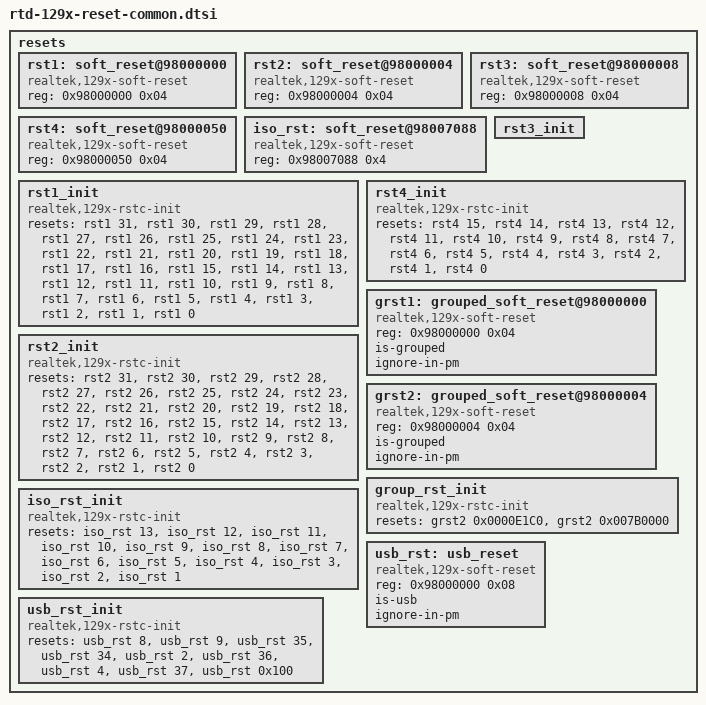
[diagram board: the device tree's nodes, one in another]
/* PLEASE include this file inside a node */
resets {
    #address-cells = <1>;
    #size-cells = <1>;
    ranges;

    /* reset_controller */
    rst1: soft_reset@98000000 {
        reg = <0x98000000 0x04>;
        compatible = "realtek,129x-soft-reset";
        #reset-cells = <1>;
    };

    rst2: soft_reset@98000004 {
        reg = <0x98000004 0x04>;
        compatible = "realtek,129x-soft-reset";
        #reset-cells = <1>;
    };

    rst3: soft_reset@98000008 {
        reg = <0x98000008 0x04>;
        compatible = "realtek,129x-soft-reset";
        #reset-cells = <1>;
    };

    rst4: soft_reset@98000050 {
        reg = <0x98000050 0x04>;
        compatible = "realtek,129x-soft-reset";
        #reset-cells = <1>;
    };

    iso_rst: soft_reset@98007088 {
        reg = <0x98007088 0x4>;
        compatible = "realtek,129x-soft-reset";
        #reset-cells = <1>;
    };

    /* reset_control */
    rst1_init {
        compatible = "realtek,129x-rstc-init";
        resets =
            <&rst1 31>, <&rst1 30>, <&rst1 29>, <&rst1 28>,
            <&rst1 27>, <&rst1 26>, <&rst1 25>, <&rst1 24>,
            <&rst1 23>, <&rst1 22>, <&rst1 21>, <&rst1 20>,
            <&rst1 19>, <&rst1 18>, <&rst1 17>, <&rst1 16>,
            <&rst1 15>, <&rst1 14>, <&rst1 13>, <&rst1 12>,
            <&rst1 11>, <&rst1 10>, <&rst1  9>, <&rst1  8>,
            <&rst1  7>, <&rst1  6>, <&rst1  5>, <&rst1  4>,
            <&rst1  3>, <&rst1  2>, <&rst1  1>, <&rst1  0>;
        reset-names =
            "rstn_rsa",          "rstn_mipi",           "rstn_nf",        "rstn_ae",
            "rstn_tp",           "rstn_md",             "rstn_cp",        "rstn_dc_phy",
            "rstn_dcu",          "rstn_se",             "rstn_lvds",      "rstn_vo",
            "rstn_tve",          "rstn_gpu",            "rstn_aio",       "rstn_etn",
            "rstn_ve3",          "rstn_ve2",            "rstn_ve1",       "rstn_hdmi",
            "sata_func_exist_0", "rstn_sata_phy_pow_0", "*rstn_usb_phy1", "*rstn_usb_phy0",
            "rstn_sata_phy_0",   "rstn_usb",            "rstn_sata_0",    "rstn_usb3_p0_mdio",
            "rstn_gspi",         "*rstn_usb3_phy0_pow", "rstn_nat",       "rstn_misc";
    };

    rst2_init {
        compatible = "realtek,129x-rstc-init";
        resets =
            <&rst2 31>, <&rst2 30>, <&rst2 29>, <&rst2 28>,
            <&rst2 27>, <&rst2 26>, <&rst2 25>, <&rst2 24>,
            <&rst2 23>, <&rst2 22>, <&rst2 21>, <&rst2 20>,
            <&rst2 19>, <&rst2 18>, <&rst2 17>, <&rst2 16>,
            <&rst2 15>, <&rst2 14>, <&rst2 13>, <&rst2 12>,
            <&rst2 11>, <&rst2 10>, <&rst2  9>, <&rst2  8>,
            <&rst2  7>, <&rst2  6>, <&rst2  5>, <&rst2  4>,
            <&rst2  3>, <&rst2  2>, <&rst2  1>, <&rst2  0>;
        reset-names =
            "rstn_sds_phy",        "rstn_cbus_tx",        "rstn_misc_sc",      "rstn_ur1",
            "rstn_ur2",            "rstn_i2c_1",          "rstn_i2c_2",        "rstn_i2c_3",
            "rstn_i2c_4",          "rstn_pcie1_nonstich", "rstn_pcie1_power",  "rstn_pcie1_core",
            "rstn_pcie1_stitch",   "rstn_i2c_5",          "rstn_pcie1",        "rstn_pcie1_phy",
            "rstn_pcie0_nonstich", "rstn_pcie0_power",    "rstn_pcie0_core",   "rstn_sdio",
            "rstn_emmc",           "rstn_cr",             "rstn_pcr_cnt",      "rstn_pcie0",
            "rstn_pcie0_phy",      "rstn_pcie0_stitch",   "rstn_usb3_p1_mdio", "*rstn_usb3_phy1_pow",
            "*rstn_usb_phy2",      "*rstn_usb_phy3",      "rstn_jpeg",         "rstn_acpu";
    };

    rst3_init {
    };

    rst4_init {
        compatible = "realtek,129x-rstc-init";
        resets =
            <&rst4 15>, <&rst4 14>, <&rst4 13>, <&rst4 12>,
            <&rst4 11>, <&rst4 10>, <&rst4  9>, <&rst4  8>,
            <&rst4  7>, <&rst4  6>, <&rst4  5>, <&rst4  4>,
            <&rst4  3>, <&rst4  2>, <&rst4  1>, <&rst4  0>;
        reset-names =
            "rstn_disp",           "rstn_pcie1_phy_mdio", "rstn_pcie0_phy_mdio", "rstn_hdmirx_wrap",
            "rstn_fan",            "rstn_sata_1",         "rstn_sata_phy_1",     "sata_func_exist_1",
            "rstn_sata_phy_pow_1", "rstn_cbusrx",         "rstn_hdmirx",         "rstn_dcphy_ssc_dig",
            "rstn_dcphy_ldo",      "rstn_dcphy_ptr",      "rstn_dcphy_alert_rx", "rstn_dcphy_crt";
    };

    iso_rst_init {
        compatible = "realtek,129x-rstc-init";
        resets =
            <&iso_rst 13>, <&iso_rst 12>, <&iso_rst 11>, <&iso_rst 10>,
            <&iso_rst  9>, <&iso_rst  8>, <&iso_rst  7>, <&iso_rst  6>,
            <&iso_rst  5>, <&iso_rst  4>, <&iso_rst  3>, <&iso_rst  2>,
            <&iso_rst  1>;
        reset-names =
            "iso_rstn_cbus",   "iso_rstn_i2c_1", "iso_rstn_i2c_0", "iso_rstn_gphy",
            "iso_rstn_gmac",   "iso_rstn_ur0",   "iso_rstn_efuse", "iso_rstn_cbusrx",
            "iso_rstn_cbustx", "iso_rstn_dp",    "iso_rstn_cec1",  "iso_rstn_cec0",
            "iso_rstn_ir";
    };

    grst1: grouped_soft_reset@98000000 {
        reg = <0x98000000 0x04>;
        compatible = "realtek,129x-soft-reset";
        #reset-cells = <1>;
        is-grouped;
        ignore-in-pm;
    };

    grst2: grouped_soft_reset@98000004 {
        reg = <0x98000004 0x04>;
        compatible = "realtek,129x-soft-reset";
        #reset-cells = <1>;
        is-grouped;
        ignore-in-pm;
    };

    group_rst_init {
        compatible = "realtek,129x-rstc-init";
        reset-names =
            "rstn_pcie0_all",
            "rstn_pcie1_all";
        resets =
            <&grst2 0x0000E1C0>,
            <&grst2 0x007B0000>;
    };

    usb_rst: usb_reset {
        reg = <0x98000000 0x08>;
        #reset-cells = <1>;
        compatible = "realtek,129x-soft-reset";
        is-usb;
        ignore-in-pm;
    };

    usb_rst_init {
       compatible = "realtek,129x-rstc-init";
       resets =
            <&usb_rst  8>,
            <&usb_rst  9>,
            <&usb_rst 35>,
            <&usb_rst 34>,
            <&usb_rst  2>,
            <&usb_rst 36>,
            <&usb_rst  4>,
            <&usb_rst 37>,
            <&usb_rst 0x100>; /* special case */
       reset-names =
            "rstn_usb_phy0",
            "rstn_usb_phy1",
            "rstn_usb_phy2",
            "rstn_usb_phy3",
            "rstn_usb3_phy0_pow",
            "rstn_usb3_phy1_pow",
            "*rstn_usb3_p0_mdio",
            "*rstn_usb3_p1_mdio",
            "rstn_usb_apply";
    };

};

